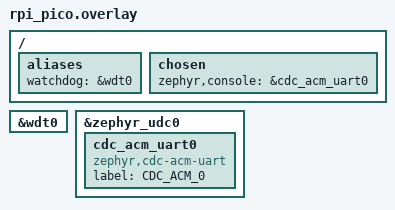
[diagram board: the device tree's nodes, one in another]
/ {
    aliases {
        watchdog = &wdt0;
    };
    chosen{
        zephyr,console = &cdc_acm_uart0;
    };
};

&wdt0 {
    status = "okay";
};

&zephyr_udc0 {
    cdc_acm_uart0: cdc_acm_uart0 {
        compatible = "zephyr,cdc-acm-uart";
        label = "CDC_ACM_0";
    };
};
